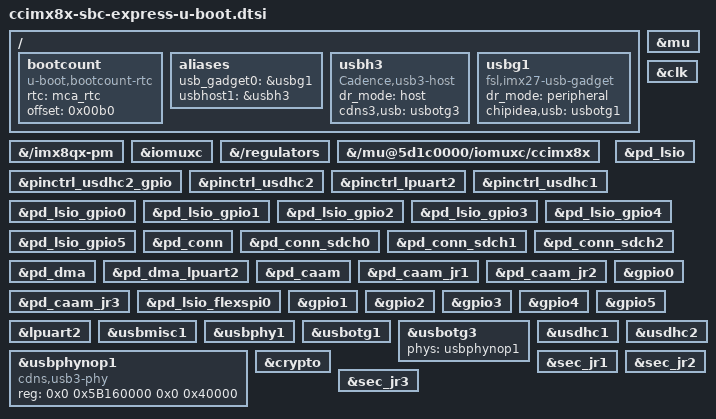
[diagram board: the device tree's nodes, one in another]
// SPDX-License-Identifier: GPL-2.0+
/*
 * Copyright 2020-2026 Digi International Inc.
 */

/ {
	bootcount {
		compatible = "u-boot,bootcount-rtc";
		rtc = <&mca_rtc>;
		offset = <0x00b0>;
	};

	aliases {
		usb_gadget0 = &usbg1;
		usbhost1 = &usbh3;
	};

	usbh3: usbh3 {
		compatible = "Cadence,usb3-host";
		dr_mode = "host";
		cdns3,usb = <&usbotg3>;
		status = "okay";
	};

	usbg1: usbg1 {
		compatible = "fsl,imx27-usb-gadget";
		dr_mode = "peripheral";
		chipidea,usb = <&usbotg1>;
		status = "okay";
		bootph-pre-ram;
	};
};

/*
 * U-Boot specific info for SPL builds
 */
&{/imx8qx-pm} {
	bootph-some-ram;
	bootph-pre-ram;
};

&mu {
	bootph-some-ram;
	bootph-pre-ram;
};

&clk {
	bootph-some-ram;
	bootph-pre-ram;
};

&iomuxc {
	bootph-some-ram;
	bootph-pre-ram;
};

&{/regulators} {
	bootph-pre-ram;
};

&{/mu@5d1c0000/iomuxc/ccimx8x} {
	bootph-some-ram;
	bootph-pre-ram;
};

&pinctrl_usdhc2_gpio {
	bootph-pre-ram;
};

&pinctrl_usdhc2 {
	bootph-pre-ram;
};

&pinctrl_lpuart2 {
	bootph-some-ram;
	bootph-pre-ram;
};

&pinctrl_usdhc1 {
	bootph-pre-ram;
};

&pd_lsio {
	bootph-pre-ram;
};

&pd_lsio_gpio0 {
	bootph-pre-ram;
};

&pd_lsio_gpio1 {
	bootph-pre-ram;
};

&pd_lsio_gpio2 {
	bootph-pre-ram;
};

&pd_lsio_gpio3 {
	bootph-pre-ram;
};

&pd_lsio_gpio4 {
	bootph-pre-ram;
};

&pd_lsio_gpio5 {
	bootph-pre-ram;
};

&pd_conn {
	bootph-pre-ram;
};

&pd_conn_sdch0 {
	bootph-pre-ram;
};

&pd_conn_sdch1 {
	bootph-pre-ram;
};

&pd_conn_sdch2 {
	bootph-pre-ram;
};

&pd_dma {
	bootph-some-ram;
	bootph-pre-ram;
};

&pd_dma_lpuart2 {
	bootph-some-ram;
	bootph-pre-ram;
};

&pd_caam {
	bootph-pre-ram;
};

&pd_caam_jr1 {
	bootph-pre-ram;
};

&pd_caam_jr2 {
	bootph-pre-ram;
};

&pd_caam_jr3 {
	bootph-pre-ram;
};

&pd_lsio_flexspi0 {
	bootph-pre-ram;
};

&gpio0 {
	bootph-pre-ram;
};

&gpio1 {
	bootph-pre-ram;
};

&gpio2 {
	bootph-pre-ram;
};

&gpio3 {
	bootph-pre-ram;
};

&gpio4 {
	bootph-pre-ram;
};

&gpio5 {
	bootph-pre-ram;
};

&lpuart2 {
	bootph-some-ram;
	bootph-pre-ram;
};

&usbmisc1 {
	bootph-pre-ram;
};

&usbphy1 {
	bootph-pre-ram;
};

&usbotg1 {
	bootph-pre-ram;
};

&usbotg3 {
	phys = <&usbphynop1>;
	bootph-pre-ram;
};

&usbphynop1 {
	compatible = "cdns,usb3-phy";
	reg = <0x0 0x5B160000 0x0 0x40000>;
	#phy-cells = <0>;
	bootph-pre-ram;
};

&usdhc1 {
	bootph-pre-ram;
};

&usdhc2 {
	bootph-pre-ram;
};

&crypto {
	bootph-pre-ram;
};

&sec_jr1 {
	bootph-pre-ram;
};

&sec_jr2 {
	bootph-pre-ram;
};

&sec_jr3 {
	bootph-pre-ram;
};
